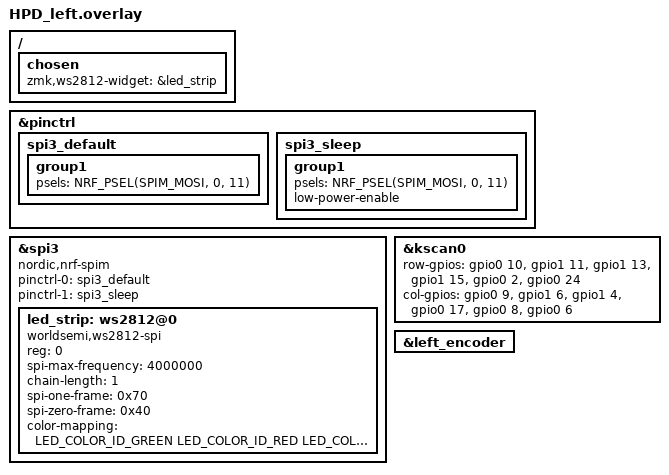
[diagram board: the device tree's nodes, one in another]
/*
 * Copyright (c) 2020 ZMK Contributors
 *
 * SPDX-License-Identifier: MIT
 */

#include "HPD.dtsi"
#include <dt-bindings/led/led.h>

/ {
    chosen {
        zmk,ws2812-widget = &led_strip;
    };
};

&pinctrl {
    spi3_default: spi3_default {
        group1 {
            psels = <NRF_PSEL(SPIM_MOSI, 0, 11)>;
        };
    };

    spi3_sleep: spi3_sleep {
        group1 {
            psels = <NRF_PSEL(SPIM_MOSI, 0, 11)>;
            low-power-enable;
        };
    };
};

&spi3 {
    compatible = "nordic,nrf-spim";
    status = "okay";

    pinctrl-0 = <&spi3_default>;
    pinctrl-1 = <&spi3_sleep>;
    pinctrl-names = "default", "sleep";

    led_strip: ws2812@0 {
        compatible = "worldsemi,ws2812-spi";

        reg = <0>;
        spi-max-frequency = <4000000>;
        
        chain-length = <1>; 
        
        spi-one-frame = <0x70>;
        spi-zero-frame = <0x40>;
        color-mapping = <LED_COLOR_ID_GREEN
                         LED_COLOR_ID_RED
                         LED_COLOR_ID_BLUE>;
    };
};

&kscan0 {
	row-gpios
        = <&gpio0 10 (GPIO_ACTIVE_HIGH | GPIO_PULL_DOWN)>
        , <&gpio1 11 (GPIO_ACTIVE_HIGH | GPIO_PULL_DOWN)>
        , <&gpio1 13 (GPIO_ACTIVE_HIGH | GPIO_PULL_DOWN)>
        , <&gpio1 15 (GPIO_ACTIVE_HIGH | GPIO_PULL_DOWN)>
        , <&gpio0 2 (GPIO_ACTIVE_HIGH | GPIO_PULL_DOWN)>
        , <&gpio0 24 (GPIO_ACTIVE_HIGH | GPIO_PULL_DOWN)>
        ;
    col-gpios
        = <&gpio0 9  GPIO_ACTIVE_HIGH>
        , <&gpio1 6  GPIO_ACTIVE_HIGH>
        , <&gpio1 4  GPIO_ACTIVE_HIGH>
        , <&gpio0 17  GPIO_ACTIVE_HIGH>
        , <&gpio0 8  GPIO_ACTIVE_HIGH>
        , <&gpio0 6  GPIO_ACTIVE_HIGH>
		;
};

    &left_encoder {
        status = "okay";
    };
